# PT32G031xx register map
File version: 0.4
Registers are 32-bit, read-write, reset 0x0 unless marked. A register's access mark holds for its fields unless they carry their own. Offsets are from the block's base; [hi:lo] are bit positions; {n}, {i} and the like mark numbered series; 'fields as' and 'values as' point back to an identical list.

## TIM8 — Advanced timer
Base 0x40006400
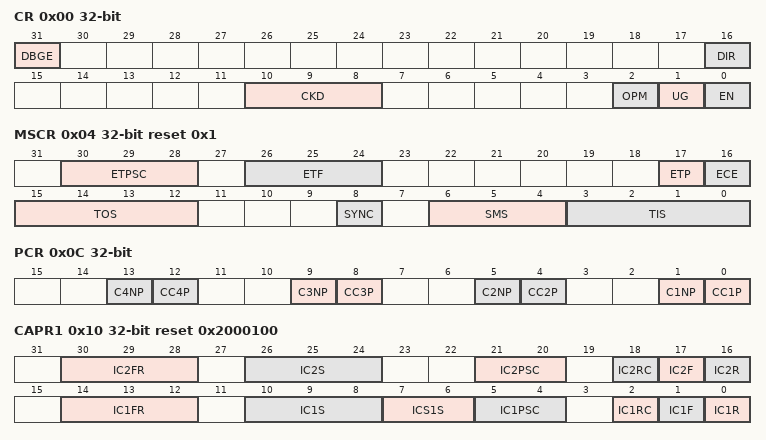
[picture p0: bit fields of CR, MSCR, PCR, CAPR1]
0x00 CR — Control Register
  [31] DBGE — TIM debug
  [16] DIR — Direction
  [10:8] CKD — Sampling clock division
  [2] OPM — One-pulse mode
  [1] UG — Update generation
  [0] EN — TIM enable
0x04 MSCR reset 0x1 — Master And Slave Mode Control Register
  [30:28] ETPSC — External trigger prescaler
  [26:24] ETF — External trigger filter
  [17] ETP — External trigger polarity
  [16] ECE — External clock enable
  [15:12] TOS — Trigger output selection
  [8] SYNC — TIM synchronization enable
  [6:4] SMS — Slave mode selection
  [3:0] TIS — Trigger input selection
0x0C PCR — Polarity Control Register
  [4n-3] C{n}NP (n=1..4) — Compare {n} complementary output polarity
  [4n-4] CC{n}P (n=1..4) — Capture/Compare {n} output polarity
0x10 CAPR1 reset 0x2000100 — Capture Configuration Register 1
  [30:28] IC2FR — Input capture 2 filter
  [26:24] IC2S — input capture 2 source selection
  [21:20] IC2PSC — Input capture 2 prescaler
  [18] IC2RC — input capture 2 capture reset conter enable
  [17] IC2F — input capture 2 falling capture enable
  [16] IC2R — input capture 2 rising capture enable
  [14:12] IC1FR — Input capture 1 filter
  [10:8] IC1S — input capture 1 source selection
  [7:6] ICS1S — ICS1 selection
  [5:4] IC1PSC — Input capture 1 prescaler
  [2] IC1RC — input capture 1 capture reset conter enable
  [1] IC1F — input capture 1 falling capture enable
  [0] IC1R — input capture 1 rising capture enable
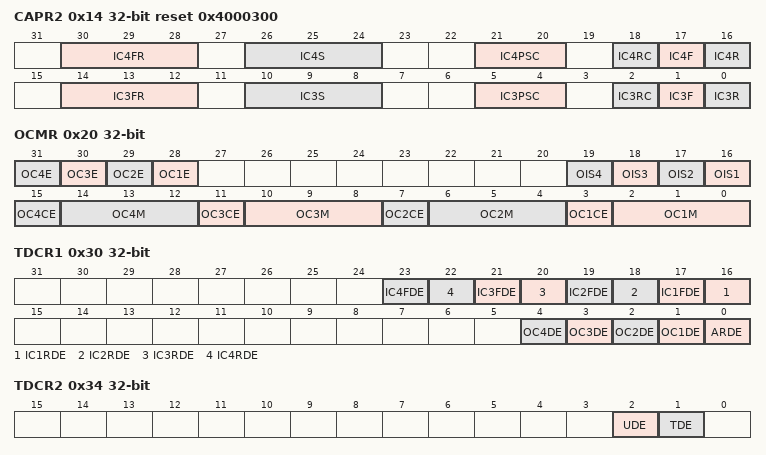
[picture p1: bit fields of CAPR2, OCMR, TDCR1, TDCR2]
0x14 CAPR2 reset 0x4000300 — Capture Configuration Register 2
  [30:28] IC4FR — Input capture 4 filter
  [26:24] IC4S — input capture 4 source selection
  [21:20] IC4PSC — Input capture 4 prescaler
  [18] IC4RC — input capture 4 capture reset conter enable
  [17] IC4F — input capture 4 falling capture enable
  [16] IC4R — input capture 4 rising capture enable
  [14:12] IC3FR — Input capture 3 filter
  [10:8] IC3S — input capture 3 source selection
  [5:4] IC3PSC — Input capture 3 prescaler
  [2] IC3RC — input capture 3 capture reset conter enable
  [1] IC3F — input capture 3 falling capture enable
  [0] IC3R — input capture 3 rising capture enable
0x20 OCMR — Output Compare Mode Register
  [n+27] OC{n}E (n=1..4) — Compare output {n} output enable
  [n+15] OIS{n} (n=1..4) — Output Idle state {n}
  [4n-1] OC{n}CE (n=1..4) — output compare {n} clear enable
  [4n-2:4n-4] OC{n}M (n=1..4) — output compare {n} mode
0x30 TDCR1 — Trigger DMA Control Register 1
  [2n+15] IC{n}FDE (n=1..4) — input capture {n} falling edge DMA request enable
  [2n+14] IC{n}RDE (n=1..4) — input capture {n} rising edge DMA request enable
  [n] OC{n}DE (n=1..4) — output compare {n} DMA request enable
  [0] ARDE — auto reload DMA request enable
0x34 TDCR2 — Trigger DMA Control Register 2
  [2] UDE — update DMA request enable
  [1] TDE — trigger DMA request enable
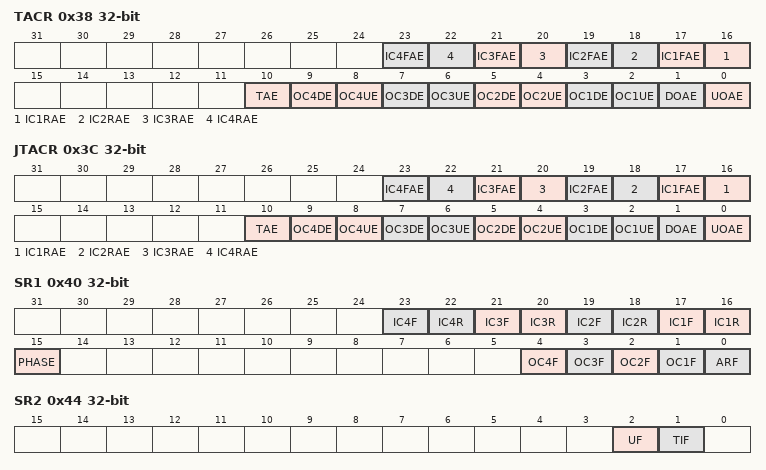
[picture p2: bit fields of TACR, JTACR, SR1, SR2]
0x38 TACR — Regular Trigger ADC Control Register
  [2n+15] IC{n}FAE (n=1..4) — IC{n}F trigger ADC enable
  [2n+14] IC{n}RAE (n=1..4) — IC{n}R trigger ADC enable
  [10] TAE — TEV trigger ADC enable
  [2n+1] OC{n}DE (n=1..4) — OC{n}D trigger ADC enable
  [2n] OC{n}UE (n=1..4) — OC{n}U trigger ADC enable
  [1] DOAE — DownOVF trigger ADC enable
  [0] UOAE — UpOVF trigger ADC enable
0x3C JTACR — Injected Trigger ADC Control Register
  fields as TACR
0x40 SR1 — Status Register 1
  [2n+15] IC{n}F (n=1..4) — Input capture {n} falling edge
  [2n+14] IC{n}R (n=1..4) — Input capture {n} rising edge
  [15] PHASE — Phase shift function flag
  [n] OC{n}F (n=1..4) — Output compare {n} flag
  [0] ARF — Auto reload flag
0x44 SR2 — Status Register 2
  [2] UF — update flag
  [1] TIF — Trigger input flag
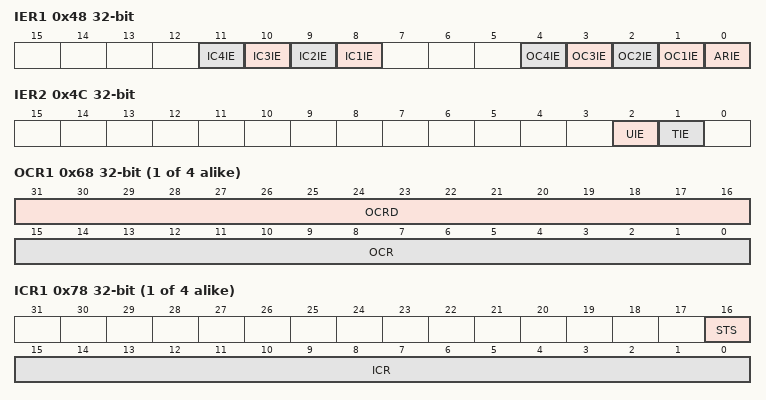
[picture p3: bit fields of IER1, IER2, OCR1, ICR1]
0x48 IER1 — Interrupt Enable Register 1
  [n+7] IC{n}IE (n=1..4) — input capture {n} interrupt enable
  [n] OC{n}IE (n=1..4) — output compare {n} interrupt enable
  [0] ARIE — Auto reload interrupt enable
0x4C IER2 — Interrupt Enable Register 2
  [2] UIE — Update interrupt enable
  [1] TIE — Trigger interrupt enable
0x50 ITARR — Interrupt Auto Reload Register
  [3:0] ITARR — TIM interrupt auto reload
0x54 ITCNTR ro — Interrupt Counter Register
  [3:0] ITCNT — TIM interrupt counter value
0x58 PSCR — Prescaler Register
  [15:0] PSC — Prescaler value
0x60 CNTR — Counter Register
  [15:0] CNT — Counter value
0x64 ARR — Auto Reload Register
  [15:0] ARR — Auto reload value
{0x64+4i} OCR{i} (i=1..4) — Output Compare Register {i}
  [31:16] OCRD — output compare value when counting down
  [15:0] OCR — output compare value
{0x74+4i} ICR{i} ro (i=1..4) — Input Capture Register {i}
  [16] STS — input capture status
  [15:0] ICR — input capture value
